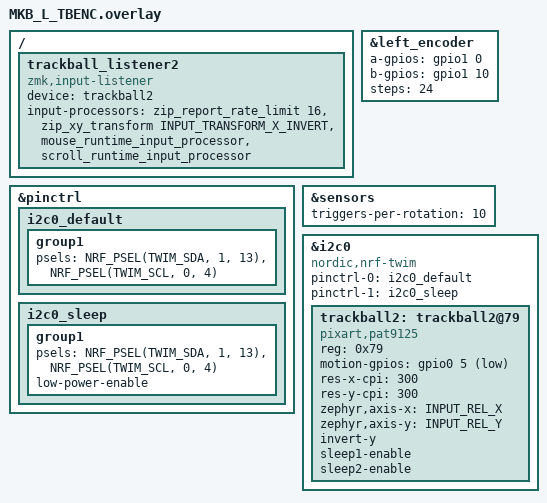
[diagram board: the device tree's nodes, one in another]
/* te9no/zmk-config-MKB2 TBENC branch を正として実装。
 *
 * PAT9125: i2c0 (nrf-twim), SDA=P1.13(D8), SCL=P0.04(D4), motion=P0.05(D5)
 * EC11:    A=gpio1 0 (P1.00), B=gpio1 10 (P1.10), steps=24
 *
 * i2c0はカスタムpinctrlを overlay内に定義。i2c1(OLED)には影響しない。
 */

#include <input/processors/report_rate_limit.dtsi>

&pinctrl {
    i2c0_default: i2c0_default {
        group1 {
            psels = <NRF_PSEL(TWIM_SDA, 1, 13)>,
                    <NRF_PSEL(TWIM_SCL, 0, 4)>;
        };
    };

    i2c0_sleep: i2c0_sleep {
        group1 {
            psels = <NRF_PSEL(TWIM_SDA, 1, 13)>,
                    <NRF_PSEL(TWIM_SCL, 0, 4)>;
            low-power-enable;
        };
    };
};

&left_encoder {
    a-gpios = <&gpio1 0 (GPIO_ACTIVE_HIGH | GPIO_PULL_UP)>;
    b-gpios = <&gpio1 10 (GPIO_ACTIVE_HIGH | GPIO_PULL_UP)>;
    steps = <24>;
    status = "okay";
};

&sensors {
    triggers-per-rotation = <10>;
};

/ {
    trackball_listener2: trackball_listener2 {
        compatible = "zmk,input-listener";
        device = <&trackball2>;
        status = "okay";
        input-processors = <&zip_report_rate_limit 16>,
                           <&zip_xy_transform INPUT_TRANSFORM_X_INVERT>,
                           <&mouse_runtime_input_processor &scroll_runtime_input_processor>;
    };
};

&i2c0 {
    status = "okay";
    compatible = "nordic,nrf-twim";
    pinctrl-0 = <&i2c0_default>;
    pinctrl-1 = <&i2c0_sleep>;
    pinctrl-names = "default", "sleep";

    trackball2: trackball2@79 {
        status = "okay";
        compatible = "pixart,pat9125";
        reg = <0x79>; /* HIGH:0x73, LOW:0x75, NC:0x79 */
        motion-gpios = <&gpio0 5 (GPIO_ACTIVE_LOW | GPIO_PULL_UP)>;
        res-x-cpi = <300>;
        res-y-cpi = <300>;
        zephyr,axis-x = <INPUT_REL_X>;
        zephyr,axis-y = <INPUT_REL_Y>;
        invert-y;
        sleep1-enable;
        sleep2-enable;
    };
};
